# R7KA8D2AD register map
Vendor: Renesas Electronics Corporation; Series: RA8; File version: 1.10.02
CPU: CM85 r0p2, little endian, MPU, FPU, VTOR, 4 interrupt priority bits, 96 interrupts
Registers are 32-bit, read-write, reset 0x0 unless marked. A register's access mark holds for its fields unless they carry their own. Offsets are from the block's base; [hi:lo] are bit positions; {n}, {i} and the like mark numbered series; 'fields as' and 'values as' point back to an identical list.

## GPTP — Generic PTP Timer
Base 0x403E0000
0x00 PTPIPV ro reset 0x3 — IP Version Register
  [31:0] IPV — IP Version
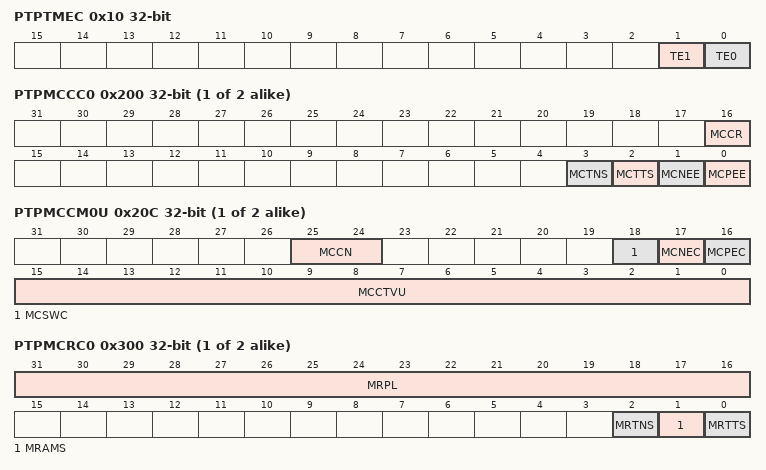
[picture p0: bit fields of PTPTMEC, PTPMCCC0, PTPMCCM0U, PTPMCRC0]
0x10 PTPTMEC — Timer Enable Configuration Register
  [1] TE1 — Timer q Enable (q = 0, 1)
    0=Timer q disabled; 1=Timer q enabled
  [0] TE0 — Timer q Enable (q = 0, 1)
    0=Timer q disabled; 1=Timer q enabled
0x14 PTPTMDC — Timer Disable Configuration Register
  [1:0] TD1 to TD0 wo — Timer n Disable (n = 0, 1)
    0=No effect; 1=Bit q of this register clears PTPTMEC.TEq
{0x20+0x40*i} PTPTIVC{i} (i=0..1) — Timer {i} Increment Value Configuration Register
  [31:0] TIV — Timer Increment Value
{0x30+0x40*i} PTPTOVC{i}L (i=0..1) — Timer {i} Offset Value Configuration Register L
  [29:0] TOVL — Timer Offset Value Lower Part
{0x34+0x40*i} PTPTOVCM{i} (i=0..1) — Timer {i} Offset Value Configuration Register M
  [31:0] TOVM — Timer Offset Value Middle Part
{0x38+0x40*i} PTPTOVC{i}U (i=0..1) — Timer {i} Offset Value Configuration Register U
  [15:0] TOVU — Timer Offset Value Upper Part
{0x40+0x40*i} PTPAVTPTM{i}L (i=0..1) ro — AVTP Timer {i} Monitoring Register L
  [31:0] AVTPL — AVTP Timer Value Lower Part
{0x44+0x40*i} PTPAVTPTM{i}U (i=0..1) ro — AVTP Timer {i} Monitoring Register U
  [31:0] AVTPU — AVTP Timer Value Upper Part
{0x50+0x40*i} PTPGPTPTM{i}L (i=0..1) ro — GPTP Timer {i} Monitoring Register L
  [29:0] GPTPL — GPTP Timer Value Lower Part
{0x54+0x40*i} PTPGPTPTM{i}M (i=0..1) ro — GPTP Timer {i} Monitoring Register M
  [31:0] GPTPM — GPTP Timer Value Middle Part
{0x58+0x40*i} PTPGPTPTM{i}U (i=0..1) ro — GPTP Timer {i} Monitoring Register U
  [15:0] GPTPU — GPTP Timer Value Upper Part
{0x200+0x10*i} PTPMCCC{i} (i=0..1) — Media Clock {i} Capture Configuration Register
  [16] MCCR — Media Clock Capture Request
  [3] MCTNS — Media Clock Capture Timer Number Select
  [2] MCTTS — Media Clock Capture Timer Type Select
    0=Timer value is captured on GPTP timer; 1=Timer value is captured on AVTP timer
  [1] MCNEE — Media Clock Capture Negative Edge Enable
    0=Timer value is not captured on negative edge of MEDIA_IN[m] signal; 1=Timer value is captured on negative edge of MEDIA_IN[m] signal
  [0] MCPEE — Media Clock Capture Positive Edge Enable
    0=Timer value is not captured on positive edge of MEDIA_IN[m] signal; 1=Timer value is captured on positive edge of MEDIA_IN[m] signal
{0x204+0x10*i} PTPMCCM{i}L (i=0..1) ro — Media Clock {i} Capture Monitoring Register L
  [31:0] MCCTVL — Media Clock Captured Timer Value Lower Part
{0x208+0x10*i} PTPMCCM{i}M (i=0..1) ro — Media Clock {i} Capture Monitoring Register M
  [31:0] MCCTVM — Media Clock Captured Timer Value Middle Part
{0x20C+0x10*i} PTPMCCM{i}U (i=0..1) ro — Media Clock {i} Capture Monitoring Register U
  [25:24] MCCN — Media Clock Capture Number
  [18] MCSWC — Media Clock Software Captured
  [17] MCNEC — Media Clock Negative Edge Captured
  [16] MCPEC — Media Clock Positive Edge Captured
  [15:0] MCCTVU — Media Clock Captured Timer Value Upper Part
{0x300+0x10*i} PTPMCRC{i} (i=0..1) — Media Clock {i} Recovery Configuration Register
  [31:16] MRPL — Media Clock Recovery Pulse Length
  [2] MRTNS — Media Clock Recovery Timer Number Select
  [1] MRAMS — Media Clock Recovery AVTP Mode Select
    0=64-bit AVTP is used for comparison; 1=32-bit AVTP is used for comparison
  [0] MRTTS — Media Clock Recovery Timer Type Select
    0=Timer value is compared to GPTP timer; 1=Timer value is compared to AVTP timer
{0x304+0x10*i} PTPMCRTC{i}L (i=0..1) — Media Clock {i} Recovery Time Configuration Register L
  [31:0] MRTVL — Media Clock Recovery Timer Value Lower Part
{0x308+0x10*i} PTPMCRTC{i}M (i=0..1) — Media Clock {i} Recovery Time Configuration Register M
  [31:0] MRTVM — Media Clock Recovery Timer Value Middle Part
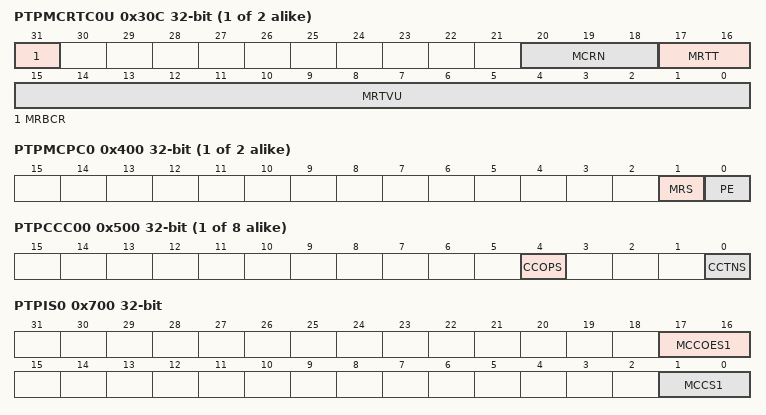
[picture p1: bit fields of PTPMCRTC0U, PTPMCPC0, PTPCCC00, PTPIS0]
{0x30C+0x10*i} PTPMCRTC{i}U (i=0..1) — Media Clock {i} Recovery Time Configuration Register U
  [31] MRBCR ro — Media Clock Recovery Buffer Clear Request
  [20:18] MCRN ro — Media Clock Recovery Number
  [17:16] MRTT — Media Clock Recovery Trigger Type
    0=When timer match, time recovery pin is set to 1; 1=When timer match, time recovery pin is set to 0; 2=When timer match, time recovery pin is inverted; 3=When timer match, a positive pulse of length PTPMCRCm.MRPL is output on time recovery pin
  [15:0] MRTVU — Media Clock Recovery Timer Value Upper Part
{0x400+4i} PTPMCPC{i} (i=0..1) — Media Clock {i} Pin Configuration Register
  [1] MRS — Media Clock Recovery Select
  [0] PE — Pin Enable
    0=MEDIA_OUT[p] fixed to 0; 1=MEDIA_OUT[p] outputs the comparison result of PTPMCPCm.MRS Recovery logic
{0x500+8i} PTPCCC{i}0 (i=0..7) — Cyclic Compare {i} Configuration Register 0 (c = 0 to 7)
  [4] CCOPS — Cyclic Compare Output Pin Select
  [0] CCTNS — Cyclic Compare Timer Number Select
{0x504+8i} PTPCCC{i}1 (i=0..7) — Cyclic Compare {i} Configuration Register 1 (c = 0 to 7)
  [31:0] CCV — Cycle Compare Value
0x700 PTPIS0 — Interrupt Status Register 0
  [17:16] MCCOES1 to MCCOES0 — Media Clock n Capture Overflow Error Status Flag (n = 0, 1)
  [1:0] MCCS1 to MCCS0 — Media Clock n Capture Status Flag (n = 0, 1)
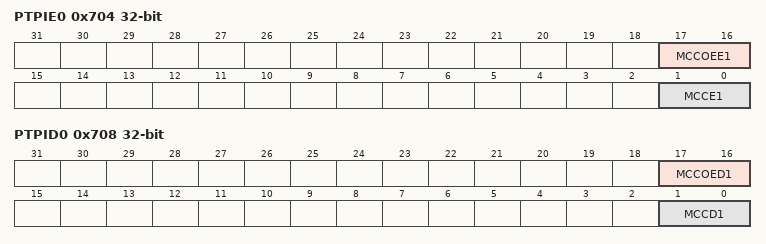
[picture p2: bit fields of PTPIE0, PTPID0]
0x704 PTPIE0 — Interrupt Enable Register 0
  [17:16] MCCOEE1 to MCCOEE0 — Media Clock m Capture Overflow Error Enable (m = 0, 1)
    0=Interrupt m disabled; 1=Interrupt m enabled
  [1:0] MCCE1 to MCCE0 — Media Clock m Capture Enable (m = 0, 1)
    0=Interrupt m disabled; 1=Interrupt m enabled
0x708 PTPID0 ro — Interrupt Disable Register 0
  [17:16] MCCOED1 to MCCOED0 — Media Clock m Capture Overflow Error Disable (m = 0, 1)
  [1:0] MCCD1 to MCCD0 — Media Clock m Capture Disable (m = 0, 1)
0x710 PTPIS1 — Interrupt Status Register 1
  [1:0] MCRMS1 to MCRMS0 — Media Clock m Recovery Match Status Flag (m = 0, 1)
0x714 PTPIE1 — Interrupt Enable Register 1
  [1:0] MCRME1 to MCRME0 — Media Clock m Recovery Match Enable (m = 0, 1)
    0=Interrupt m disabled; 1=Interrupt m enabled
0x718 PTPID1 ro — Interrupt Disable Register 1
  [1:0] MCRMD1 to MCRMD0 — Media Clock m Recovery Match Disable (m = 0, 1)
0x1000 POTCFGR — Pulse Output Timer Configuration Register
  [0] REFSEL — Reference Timer Select
    0=Select and use the reference time of GPTP timer 0; 1=Select and use the reference time of GPTP timer 1
{0x1004+0x30*i} POTCR{i} (i=0..3) — Pulse Output Timer Control Register {i}
  [0] START — Pulse Output Enable
    0=Pulse output stop; 1=Pulse output permission
{0x1008+0x30*i} POTSTR{i}U (i=0..3) — Pulse Output Start Time Setting Register nU
{0x100C+0x30*i} POTSTR{i}M (i=0..3) — Pulse Output Start Time Setting Register nM
{0x1010+0x30*i} POTSTR{i}L (i=0..3) — Pulse Output Start Time Setting Register nL
{0x1014+0x30*i} POTPER{i}U (i=0..3) — Period Setting Register nU
{0x1018+0x30*i} POTPER{i}M (i=0..3) — Period Setting Register nM
{0x101C+0x30*i} POTPER{i}L (i=0..3) — Period Setting Register nL
{0x1020+0x30*i} POTPWR{i} (i=0..3) — Pulse Width Setting Register {i}
{0x1028+0x30*i} POTCPR{i}U (i=0..3) ro — Time Capture Register nU
{0x102C+0x30*i} POTCPR{i}M (i=0..3) ro — Time Capture Register nM
{0x1030+0x30*i} POTCPR{i}L (i=0..3) ro — Time Capture Register nL

## GPTP_NS — Generic PTP Timer
Base 0x503E0000
Registers as GPTP; these are added or differ:
{0x50+0x40*i} PTPGPTPTM{i}L (i=0..1) ro — GPTP Timer {i} Monitoring Register L
  [29:0] GPTPL — GPTP Timer Value Lower Part
{0x54+0x40*i} PTPGPTPTM{i}M (i=0..1) ro — GPTP Timer {i} Monitoring Register M
  [31:0] GPTPM — GPTP Timer Value Middle Part
{0x58+0x40*i} PTPGPTPTM{i}U (i=0..1) ro — GPTP Timer {i} Monitoring Register U
  [15:0] GPTPU — GPTP Timer Value Upper Part
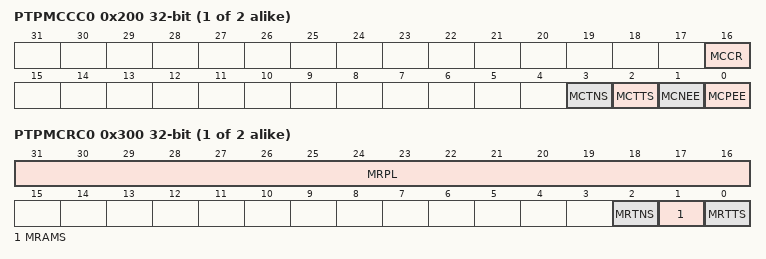
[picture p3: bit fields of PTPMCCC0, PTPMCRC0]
{0x200+0x10*i} PTPMCCC{i} (i=0..1) — Media Clock {i} Capture Configuration Register
  fields as GPTP.PTPMCCC0
{0x300+0x10*i} PTPMCRC{i} (i=0..1) — Media Clock {i} Recovery Configuration Register
  fields as GPTP.PTPMCRC0
0x1000 POTCFGR — Pulse Output Timer Configuration Register
  [0] REFSEL — Reference Timer Select
    0=Select and use the reference time of GPTP timer 0; 1=Select and use the reference time of GPTP timer 1
